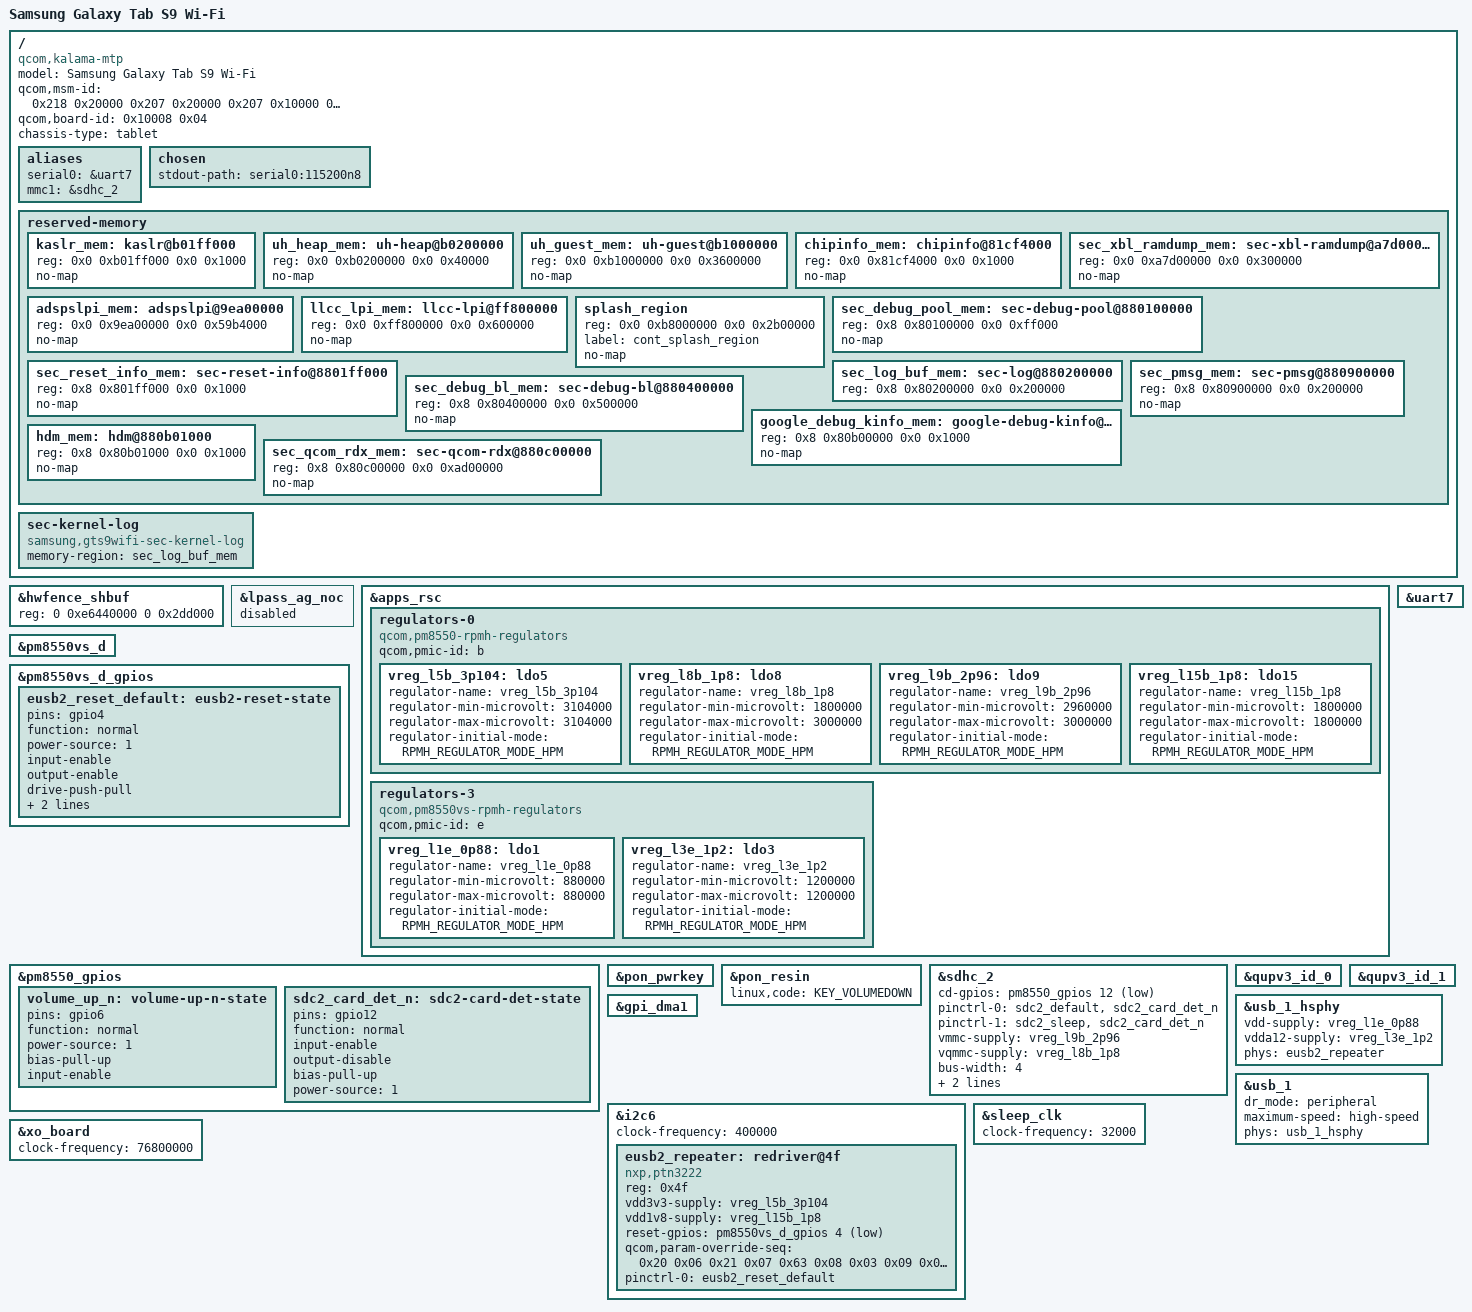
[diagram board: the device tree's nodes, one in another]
// SPDX-License-Identifier: BSD-3-Clause
/* Galaxy Tab S9 Wi-Fi (SM-X710), board revisions 04..20.
 * Derived from the S9 Ultra bring-up tree; parameters checked against the
 * owner's vendor_boot DTB + current DTBO overlay 1, captured 2026-09-18.
 * This is an experimental bring-up tree, not a tested desktop port.
 */
/dts-v1/;
#include <dt-bindings/gpio/gpio.h>
#include <dt-bindings/input/input.h>
#include <dt-bindings/pinctrl/qcom,pmic-gpio.h>
#include <dt-bindings/regulator/qcom,rpmh-regulator.h>
#include "sm8550.dtsi"
#include "pm8550.dtsi"
#include "pm8550vs.dtsi"
#include "pmk8550.dtsi"
/delete-node/ &adspslpi_mem;
/ {
 model = "Samsung Galaxy Tab S9 Wi-Fi";
 compatible = "qcom,kalama-mtp", "qcom,kalama", "qcom,mtp",
              "samsung,gts9wifi", "qcom,sm8550";
 qcom,msm-id = <0x218 0x20000 0x207 0x20000 0x207 0x10000 0x218 0x10000>;
 qcom,board-id = <0x10008 0x04>;
 chassis-type = "tablet";
 aliases { serial0 = &uart7; mmc1 = &sdhc_2; };
 chosen { stdout-path = "serial0:115200n8"; };
	reserved-memory {
		/*
		 * Samsung ABL patches the /memory ranges but, without the stock
		 * overlay, does not add the board-only protected carveouts below.
		 * Keep them out of the buddy allocator: touching one of these ranges
		 * can make the secure firmware reset the SoC with a fatal NoC error.
		 */
		kaslr_mem: kaslr@b01ff000 {
			reg = <0x0 0xb01ff000 0x0 0x1000>;
			no-map;
		};

		uh_heap_mem: uh-heap@b0200000 {
			reg = <0x0 0xb0200000 0x0 0x40000>;
			no-map;
		};

		uh_guest_mem: uh-guest@b1000000 {
			reg = <0x0 0xb1000000 0x0 0x3600000>;
			no-map;
		};

		chipinfo_mem: chipinfo@81cf4000 {
			reg = <0x0 0x81cf4000 0x0 0x1000>;
			no-map;
		};

		sec_xbl_ramdump_mem: sec-xbl-ramdump@a7d00000 {
			reg = <0x0 0xa7d00000 0x0 0x300000>;
			no-map;
		};

		adspslpi_mem: adspslpi@9ea00000 {
			reg = <0x0 0x9ea00000 0x0 0x59b4000>;
			no-map;
		};

		llcc_lpi_mem: llcc-lpi@ff800000 {
			reg = <0x0 0xff800000 0x0 0x600000>;
			no-map;
		};

		/* X710 ABL expects this exact downstream node name and label. */
		splash_region {
			reg = <0x0 0xb8000000 0x0 0x2b00000>;
			label = "cont_splash_region";
			no-map;
		};

		sec_debug_pool_mem: sec-debug-pool@880100000 {
			reg = <0x8 0x80100000 0x0 0xff000>;
			no-map;
		};

		sec_reset_info_mem: sec-reset-info@8801ff000 {
			reg = <0x8 0x801ff000 0x0 0x1000>;
			no-map;
		};

		/* Shared with Samsung bootloader and recovery for /proc/last_kmsg. */
		sec_log_buf_mem: sec-log@880200000 {
			reg = <0x8 0x80200000 0x0 0x200000>;
		};

		sec_debug_bl_mem: sec-debug-bl@880400000 {
			reg = <0x8 0x80400000 0x0 0x500000>;
			no-map;
		};

		sec_pmsg_mem: sec-pmsg@880900000 {
			reg = <0x8 0x80900000 0x0 0x200000>;
			no-map;
		};

		google_debug_kinfo_mem: google-debug-kinfo@880b00000 {
			reg = <0x8 0x80b00000 0x0 0x1000>;
			no-map;
		};

		hdm_mem: hdm@880b01000 {
			reg = <0x8 0x80b01000 0x0 0x1000>;
			no-map;
		};

		sec_qcom_rdx_mem: sec-qcom-rdx@880c00000 {
			reg = <0x8 0x80c00000 0x0 0xad00000>;
			no-map;
		};
	};
 sec-kernel-log {
  compatible = "samsung,gts9wifi-sec-kernel-log";
  memory-region = <&sec_log_buf_mem>;
 };
};
&hwfence_shbuf { reg = <0 0xe6440000 0 0x2dd000>; };
&lpass_ag_noc { status = "disabled"; };
&apps_rsc {
 regulators-0 {
  compatible = "qcom,pm8550-rpmh-regulators";
  qcom,pmic-id = "b";
  vreg_l5b_3p104: ldo5 { regulator-name = "vreg_l5b_3p104"; regulator-min-microvolt = <3104000>; regulator-max-microvolt = <3104000>; regulator-initial-mode = <RPMH_REGULATOR_MODE_HPM>; };
  vreg_l8b_1p8: ldo8 { regulator-name = "vreg_l8b_1p8"; regulator-min-microvolt = <1800000>; regulator-max-microvolt = <3000000>; regulator-initial-mode = <RPMH_REGULATOR_MODE_HPM>; };
  vreg_l9b_2p96: ldo9 { regulator-name = "vreg_l9b_2p96"; regulator-min-microvolt = <2960000>; regulator-max-microvolt = <3000000>; regulator-initial-mode = <RPMH_REGULATOR_MODE_HPM>; };
  vreg_l15b_1p8: ldo15 { regulator-name = "vreg_l15b_1p8"; regulator-min-microvolt = <1800000>; regulator-max-microvolt = <1800000>; regulator-initial-mode = <RPMH_REGULATOR_MODE_HPM>; };
 };
 regulators-3 {
 compatible = "qcom,pm8550vs-rpmh-regulators"; qcom,pmic-id = "e";
 vreg_l1e_0p88: ldo1 { regulator-name = "vreg_l1e_0p88"; regulator-min-microvolt = <880000>; regulator-max-microvolt = <880000>; regulator-initial-mode = <RPMH_REGULATOR_MODE_HPM>; };
 vreg_l3e_1p2: ldo3 { regulator-name = "vreg_l3e_1p2"; regulator-min-microvolt = <1200000>; regulator-max-microvolt = <1200000>; regulator-initial-mode = <RPMH_REGULATOR_MODE_HPM>; };
 };
};
&pm8550vs_d {
	status = "okay";
};
&pm8550vs_d_gpios {
	eusb2_reset_default: eusb2-reset-state {
		pins = "gpio4";
		function = "normal";
		power-source = <1>;
		input-enable;
		output-enable;
		drive-push-pull;
		qcom,drive-strength = <PMIC_GPIO_STRENGTH_MED>;
		bias-disable;
	};
};
&pm8550_gpios {
	volume_up_n: volume-up-n-state {
		pins = "gpio6";
		function = "normal";
		power-source = <1>;
		bias-pull-up;
		input-enable;
	};

	sdc2_card_det_n: sdc2-card-det-state {
		pins = "gpio12";
		function = "normal";
		input-enable;
		output-disable;
		bias-pull-up;
		power-source = <1>; /* 1.8 V */
	};
};
&pon_pwrkey {
	status = "okay";
};
&pon_resin {
	linux,code = <KEY_VOLUMEDOWN>;
	status = "okay";
};
&sdhc_2 {
	cd-gpios = <&pm8550_gpios 12 GPIO_ACTIVE_LOW>;
	pinctrl-names = "default", "sleep";
	pinctrl-0 = <&sdc2_default &sdc2_card_det_n>;
	pinctrl-1 = <&sdc2_sleep &sdc2_card_det_n>;
	vmmc-supply = <&vreg_l9b_2p96>;
	vqmmc-supply = <&vreg_l8b_1p8>;
	bus-width = <4>;
	no-sdio;
	no-mmc;
	status = "okay";
};
&uart7 {
	status = "okay";
};
&qupv3_id_0 { status = "okay"; };
&qupv3_id_1 { status = "okay"; };
&gpi_dma1 { status = "okay"; };
&i2c6 {
 clock-frequency = <400000>; status = "okay";
 eusb2_repeater: redriver@4f {
  compatible = "nxp,ptn3222"; reg = <0x4f>; #phy-cells = <0>;
  vdd3v3-supply = <&vreg_l5b_3p104>;
  vdd1v8-supply = <&vreg_l15b_1p8>;
  reset-gpios = <&pm8550vs_d_gpios 4 GPIO_ACTIVE_LOW>;
  /* S9 has FIVE value/register pairs; Ultra's four-pair table differs. */
  qcom,param-override-seq = <0x20 0x06 0x21 0x07 0x63 0x08
                           0x03 0x09 0x01 0x0a>;
  pinctrl-names = "default"; pinctrl-0 = <&eusb2_reset_default>;
 };
};
&usb_1_hsphy {
 vdd-supply = <&vreg_l1e_0p88>; vdda12-supply = <&vreg_l3e_1p2>;
 phys = <&eusb2_repeater>; status = "okay";
};
/* Force the initial diagnostic port to USB2 peripheral mode. */
&usb_1 {
 dr_mode = "peripheral"; maximum-speed = "high-speed";
 phys = <&usb_1_hsphy>; phy-names = "usb2-phy";
 status = "okay";
};
&sleep_clk { clock-frequency = <32000>; };
&xo_board { clock-frequency = <76800000>; };
/* Display, STM touchscreen, Wacom, charging, WLAN and DSPs stay disabled.
 * Their downstream facts are recorded in device/stock-hardware.json.
 * UFS stays disabled: the diagnostic initramfs runs entirely in RAM.
 */
